# SIBG301M104LIL register map
Vendor: Silicon Labs; Series: Si; File version: B
Registers are 32-bit, read-write, reset 0x0 unless marked. A register's access mark holds for its fields unless they carry their own. Offsets are from the block's base; [hi:lo] are bit positions; 'fields as' and 'values as' point back to an identical list.

## EMU_NS — EMU_NS Registers
Base 0xA3008000
Same registers: EMU_S 0xB3008000
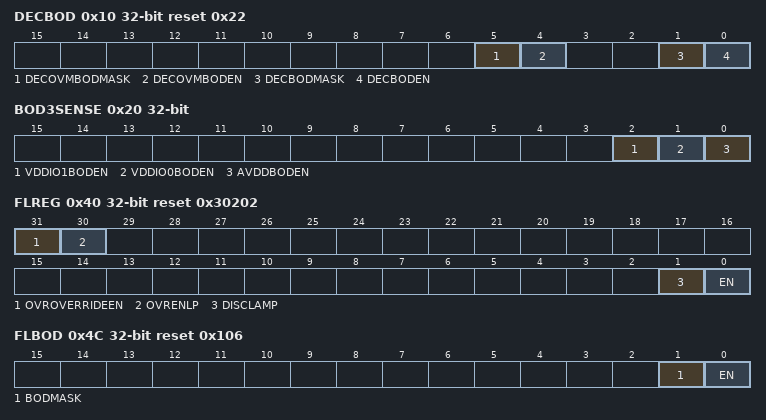
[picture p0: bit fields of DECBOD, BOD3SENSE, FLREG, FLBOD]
0x10 DECBOD reset 0x22
  [5] DECOVMBODMASK — Over Voltage Monitor Mask
  [4] DECOVMBODEN — Over Voltage Monitor enable
  [1] DECBODMASK
  [0] DECBODEN — DECBOD enable
0x20 BOD3SENSE
  [2] VDDIO1BODEN — VDDIO1 BOD enable
  [1] VDDIO0BODEN — VDDIO0 BOD enable
  [0] AVDDBODEN — AVDD BOD enable
0x40 FLREG reset 0x30202
  [31] OVROVERRIDEEN — Enable Override
  [30] OVRENLP — Override Low Power Enable
  [1] DISCLAMP — Disable soft pulldown
  [0] EN — Enable FLREG
0x4C FLBOD reset 0x106
  [1] BODMASK — FLBOD Mask
  [0] EN — FLBOD Enable
0x5C IPVERSION ro reset 0x9
0x60 LOCK wo reset 0xADE8
  [15:0] LOCKKEY
    0xADE8=UNLOCK (Unlock EMU register)
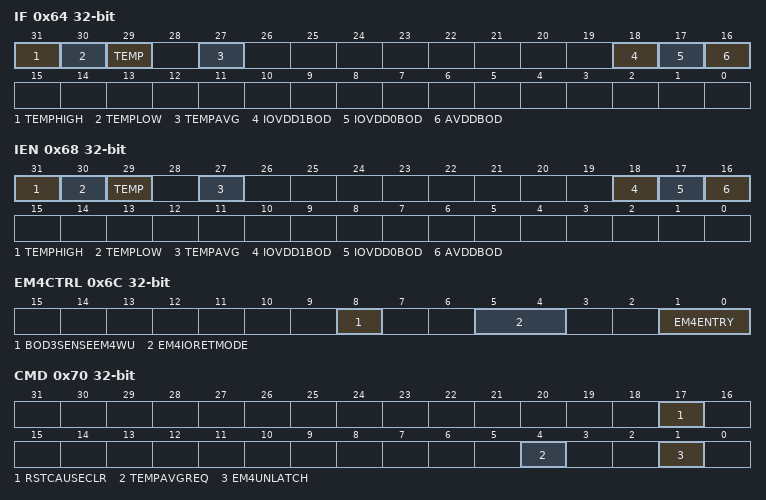
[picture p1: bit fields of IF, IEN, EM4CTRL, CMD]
0x64 IF
  [31] TEMPHIGH — Temperature high Interrupt flag
  [30] TEMPLOW — Temperature low Interrupt flag
  [29] TEMP — Temperature Interrupt flag
  [27] TEMPAVG — Temperature Average Interrupt flag
  [18] IOVDD1BOD — VDDIO1 BOD Interrupt flag
  [17] IOVDD0BOD — VDDIO0 BOD Interrupt flag
  [16] AVDDBOD — AVDD BOD Interrupt flag
0x68 IEN
  [31] TEMPHIGH — Temperature high Interrupt enable
  [30] TEMPLOW — Temperature low Interrupt enable
  [29] TEMP — Temperature Interrupt enable
  [27] TEMPAVG — Temperature Interrupt enable
  [18] IOVDD1BOD — VDDIO1 BOD Interrupt enable
  [17] IOVDD0BOD — VDDIO0 BOD Interrupt enable
  [16] AVDDBOD — AVDD BOD Interrupt enable
0x6C EM4CTRL
  [8] BOD3SENSEEM4WU — Set BOD3SENSE as EM4 wakeup
  [5:4] EM4IORETMODE — EM4 IO retention mode
    0=DISABLE (No Retention: Pads enter reset state when entering EM4); 1=EM4EXIT (Retention through EM4: Pads enter reset state when exiting EM4); 2=SWUNLATCH (Retention through EM4 and Wakeup: software writes UNLATCH register to remove retention)
  [1:0] EM4ENTRY — EM4 entry request
0x70 CMD wo
  [17] RSTCAUSECLR — Reset Cause Clear
  [4] TEMPAVGREQ — Temperature Average Request
  [1] EM4UNLATCH
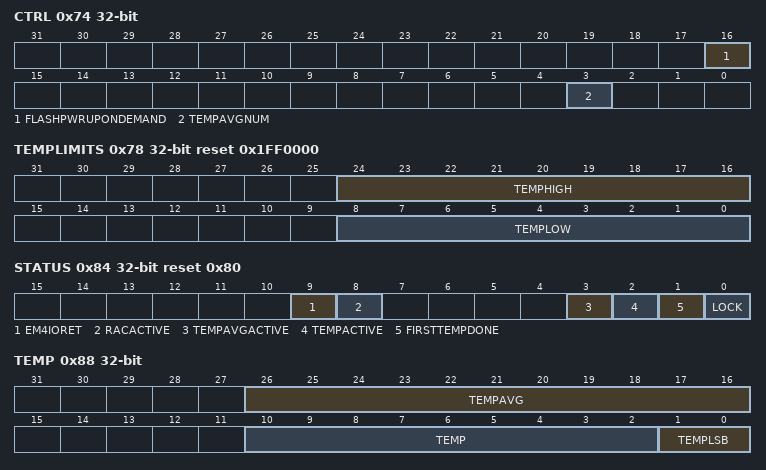
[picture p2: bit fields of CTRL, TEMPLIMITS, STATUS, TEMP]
0x74 CTRL
  [16] FLASHPWRUPONDEMAND — Enable flash on demand wakeup
  [3] TEMPAVGNUM — Averaged Temperature samples num
    0=N16 (16 measurements); 1=N64 (64 measurements)
0x78 TEMPLIMITS reset 0x1FF0000
  [24:16] TEMPHIGH — Temp High limit
  [8:0] TEMPLOW — Temp Low limit
0x84 STATUS ro reset 0x80
  [9] EM4IORET — EM4 IO retention status
  [8] RACACTIVE
  [3] TEMPAVGACTIVE — Temp Average active
  [2] TEMPACTIVE
  [1] FIRSTTEMPDONE
  [0] LOCK — Lock status
    0=UNLOCKED (All EMU lockable registers are unlocked.); 1=LOCKED (All EMU lockable registers are locked.)
0x88 TEMP ro
  [26:16] TEMPAVG — Averaged Temperature
  [10:2] TEMP — Temperature measured
  [1:0] TEMPLSB — Temperature measured decimal part
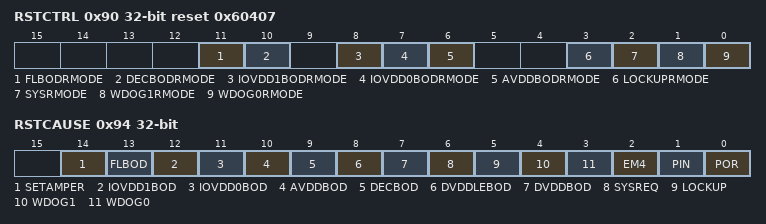
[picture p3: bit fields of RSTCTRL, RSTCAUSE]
0x90 RSTCTRL reset 0x60407
  [11] FLBODRMODE — Enable FLBOD reset
    0=DISABLED (Reset request is blocked); 1=ENABLED (The entire device is reset)
  [10] DECBODRMODE — Enable DECBOD reset
    values as FLBODRMODE
  [8] IOVDD1BODRMODE — Enable VDDIO1 BOD reset
    0=DISABLED (Reset request is blocked); 1=ENABLED (The entire device is reset except some EMU registers)
  [7] IOVDD0BODRMODE — Enable VDDIO0 BOD reset
    values as IOVDD1BODRMODE
  [6] AVDDBODRMODE — Enable AVDD BOD reset
    0=DISABLED (Reset Request is block); 1=ENABLED (The entire device is reset except some EMU registers)
  [3] LOCKUPRMODE — Enable M33 Lockup reset
    0=DISABLED (Reset Request is Block); 1=ENABLED (The entire device is reset except some EMU registers)
  [2] SYSRMODE — Enable M33 System reset
    0=DISABLED (Reset request is blocked); 1=ENABLED (Device is reset except some EMU registers)
  [1] WDOG1RMODE — Enable WDOG1 reset
    values as IOVDD1BODRMODE
  [0] WDOG0RMODE — Enable WDOG0 reset
    values as IOVDD1BODRMODE
0x94 RSTCAUSE ro
  [14] SETAMPER — SE Tamper event Reset
  [13] FLBOD — FLBOD Reset
  [12] IOVDD1BOD — LEBOD3 Reset
  [11] IOVDD0BOD — LEBOD2 Reset
  [10] AVDDBOD — LEBOD1 Reset
  [9] DECBOD — LVBOD Reset
  [8] DVDDLEBOD — LEBOD Reset
  [7] DVDDBOD — HVBOD Reset
  [6] SYSREQ — M33 Core Sys Reset
  [5] LOCKUP — M33 Core Lockup Reset
  [4] WDOG1 — Watchdog 1 Reset
  [3] WDOG0 — Watchdog 0 Reset
  [2] EM4 — EM4 Wakeup Reset
  [1] PIN — Pin Reset
  [0] POR — Power On Reset
